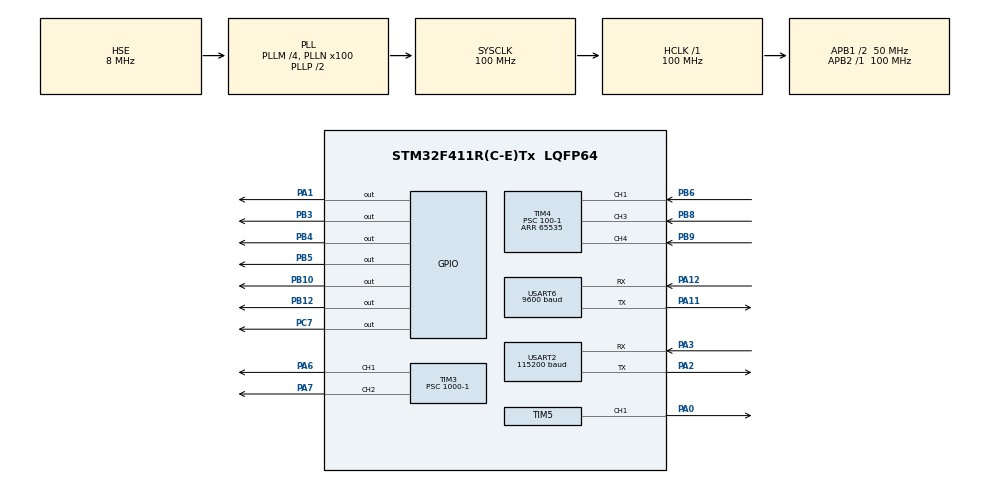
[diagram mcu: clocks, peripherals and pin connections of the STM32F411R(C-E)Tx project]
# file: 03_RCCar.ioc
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Dma.Request0=USART6_RX
Dma.USART6_RX.0.Direction=DMA_PERIPH_TO_MEMORY
Dma.USART6_RX.0.FIFOMode=DMA_FIFOMODE_DISABLE
Dma.USART6_RX.0.Instance=DMA2_Stream1
Dma.USART6_RX.0.MemDataAlignment=DMA_MDATAALIGN_BYTE
Dma.USART6_RX.0.MemInc=DMA_MINC_ENABLE
Dma.USART6_RX.0.Mode=DMA_NORMAL
Dma.USART6_RX.0.PeriphDataAlignment=DMA_PDATAALIGN_BYTE
Dma.USART6_RX.0.PeriphInc=DMA_PINC_DISABLE
Dma.USART6_RX.0.Priority=DMA_PRIORITY_LOW
FREERTOS.Tasks01=defaultTask,24,128,StartDefaultTask,Default,NULL,Dynamic,NULL,NULL;UltrasonicTask,24,128,Ultrasonic,Default,NULL,Dynamic,NULL,NULL;AutoRunTask,24,128,AutoRun,Default,NULL,Dynamic,NULL,NULL;BuzzerTask,24,128,Buzzer,Default,NULL,Dynamic,NULL,NULL
FREERTOS.configUSE_NEWLIB_REENTRANT=1
Mcu.Family=STM32F4
Mcu.Name=STM32F411R(C-E)Tx
Mcu.Package=LQFP64
NVIC.DMA2_Stream1_IRQn=true\:5\:0\:false\:false\:true\:true\:false\:true\:true
NVIC.PriorityGroup=NVIC_PRIORITYGROUP_4
NVIC.TIM1_UP_TIM10_IRQn=true\:15\:0\:false\:false\:true\:false\:true\:true\:true
NVIC.TIM4_IRQn=true\:5\:0\:false\:false\:true\:true\:true\:true\:true
NVIC.TimeBase=TIM1_UP_TIM10_IRQn
NVIC.TimeBaseIP=TIM10
NVIC.USART2_IRQn=true\:5\:0\:false\:false\:true\:true\:true\:true\:true
NVIC.USART6_IRQn=true\:5\:0\:false\:false\:true\:true\:true\:true\:true
PA0-WKUP.Signal=S_TIM5_CH1
PA1.Signal=GPIO_Output
PA11.Mode=Asynchronous
PA11.Signal=USART6_TX
PA12.Mode=Asynchronous
PA12.Signal=USART6_RX
PA13.Mode=Serial_Wire
PA13.Signal=SYS_JTMS-SWDIO
PA14.Mode=Serial_Wire
PA14.Signal=SYS_JTCK-SWCLK
PA2.Mode=Asynchronous
PA2.Signal=USART2_TX
PA3.Mode=Asynchronous
PA3.Signal=USART2_RX
PA6.Signal=S_TIM3_CH1
PA7.Signal=S_TIM3_CH2
PB10.Signal=GPIO_Output
PB12.Signal=GPIO_Output
PB3.Signal=GPIO_Output
PB4.Signal=GPIO_Output
PB5.Signal=GPIO_Output
PB6.Signal=S_TIM4_CH1
PB8.Signal=S_TIM4_CH3
PB9.Signal=S_TIM4_CH4
PC7.Signal=GPIO_Output
PH0\ -\ OSC_IN.Mode=HSE-External-Oscillator
PH0\ -\ OSC_IN.Signal=RCC_OSC_IN
PH1\ -\ OSC_OUT.Mode=HSE-External-Oscillator
PH1\ -\ OSC_OUT.Signal=RCC_OSC_OUT
ProjectManager.HeapSize=0x200
ProjectManager.StackSize=0x400
ProjectManager.TargetToolchain=STM32CubeIDE
RCC.48MHZClocksFreq_Value=50000000
RCC.AHBFreq_Value=100000000
RCC.APB1CLKDivider=RCC_HCLK_DIV2
RCC.APB1Freq_Value=50000000
RCC.APB1TimFreq_Value=100000000
RCC.APB2Freq_Value=100000000
RCC.APB2TimFreq_Value=100000000
RCC.CortexFreq_Value=100000000
RCC.HCLKFreq_Value=100000000
RCC.HSE_VALUE=8000000
RCC.HSI_VALUE=16000000
RCC.LSE_VALUE=32768
RCC.PLLM=4
RCC.PLLN=100
RCC.PLLSourceVirtual=RCC_PLLSOURCE_HSE
RCC.RCC_RTC_Clock_Source=RCC_RTCCLKSOURCE_LSI
RCC.RCC_RTC_Clock_SourceVirtual=RCC_RTCCLKSOURCE_LSI
RCC.SYSCLKFreq_VALUE=100000000
RCC.SYSCLKSource=RCC_SYSCLKSOURCE_PLLCLK
RCC.VCOOutputFreq_Value=200000000
SH.S_TIM3_CH1.0=TIM3_CH1,PWM Generation1 CH1
SH.S_TIM3_CH2.0=TIM3_CH2,PWM Generation2 CH2
SH.S_TIM4_CH1.0=TIM4_CH1,Input_Capture1_from_TI1
SH.S_TIM4_CH3.0=TIM4_CH3,Input_Capture3_from_TI3
SH.S_TIM4_CH4.0=TIM4_CH4,Input_Capture4_from_TI4
SH.S_TIM5_CH1.0=TIM5_CH1,PWM Generation1 CH1
TIM3.Channel-PWM\ Generation1\ CH1=TIM_CHANNEL_1
TIM3.Channel-PWM\ Generation2\ CH2=TIM_CHANNEL_2
TIM3.Period=1000-1
TIM3.Prescaler=1000-1
TIM4.Channel-Input_Capture1_from_TI1=TIM_CHANNEL_1
TIM4.Channel-Input_Capture3_from_TI3=TIM_CHANNEL_3
TIM4.Channel-Input_Capture4_from_TI4=TIM_CHANNEL_4
TIM4.Period=65535
TIM4.Prescaler=100-1
TIM5.Channel-PWM\ Generation1\ CH1=TIM_CHANNEL_1
TIM5.Period=1000-1
TIM5.Prescaler=0
TIM5.Pulse-PWM\ Generation1\ CH1=500-1
USART2.BaudRate=115200
USART2.VirtualMode=VM_ASYNC
USART6.BaudRate=9600
USART6.VirtualMode=VM_ASYNC
VP_FREERTOS_VS_CMSIS_V2.Mode=CMSIS_V2
VP_SYS_VS_tim10.Mode=TIM10
VP_TIM3_VS_ClockSourceINT.Mode=Internal
VP_TIM4_VS_ClockSourceINT.Mode=Internal
VP_TIM5_VS_ClockSourceINT.Mode=Internal
board=custom

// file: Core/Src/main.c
/* USER CODE BEGIN Header */
/**
  ******************************************************************************
  * @file           : main.c
  * @brief          : Main program body
  ******************************************************************************
  * @attention
  *
  * Copyright (c) 2025 STMicroelectronics.
  * All rights reserved.
  *
  * This software is licensed under terms that can be found in the LICENSE file
  * in the root directory of this software component.
  * If no LICENSE file comes with this software, it is provided AS-IS.
  *
  ******************************************************************************
  */
/* USER CODE END Header */
#include "main.h"
#include "cmsis_os.h"
#include "dma.h"
#include "tim.h"
#include "usart.h"
#include "gpio.h"

/* USER CODE BEGIN Includes */
#include "hw.h"

/* USER CODE END Includes */

void SystemClock_Config(void);
void MX_FREERTOS_Init(void);

int main(void)
{

  /* MCU Configuration--------------------------------------------------------*/

  /* Reset of all peripherals, Initializes the Flash interface and the Systick. */
  HAL_Init();

  /* Configure the system clock */
  SystemClock_Config();

  /* Initialize all configured peripherals */
  MX_GPIO_Init();
  MX_DMA_Init();
  MX_USART2_UART_Init();
  MX_USART6_UART_Init();
  MX_TIM3_Init();
  MX_TIM4_Init();
  MX_TIM5_Init();
  /* USER CODE BEGIN 2 */
  hwInit();
  /* USER CODE END 2 */

  /* Init scheduler */
  osKernelInitialize();

  /* Call init function for freertos objects (in cmsis_os2.c) */
  MX_FREERTOS_Init();

  /* Start scheduler */
  osKernelStart();

  /* We should never get here as control is now taken by the scheduler */

  /* Infinite loop */
  while (1)
  {

  }
}

void SystemClock_Config(void)
{
  RCC_OscInitTypeDef RCC_OscInitStruct = {0};
  RCC_ClkInitTypeDef RCC_ClkInitStruct = {0};

  /** Configure the main internal regulator output voltage
  */
  __HAL_RCC_PWR_CLK_ENABLE();
  __HAL_PWR_VOLTAGESCALING_CONFIG(PWR_REGULATOR_VOLTAGE_SCALE1);

  /** Initializes the RCC Oscillators according to the specified parameters
  * in the RCC_OscInitTypeDef structure.
  */
  RCC_OscInitStruct.OscillatorType = RCC_OSCILLATORTYPE_HSE;
  RCC_OscInitStruct.HSEState = RCC_HSE_ON;
  RCC_OscInitStruct.PLL.PLLState = RCC_PLL_ON;
  RCC_OscInitStruct.PLL.PLLSource = RCC_PLLSOURCE_HSE;
  RCC_OscInitStruct.PLL.PLLM = 4;
  RCC_OscInitStruct.PLL.PLLN = 100;
  RCC_OscInitStruct.PLL.PLLP = RCC_PLLP_DIV2;
  RCC_OscInitStruct.PLL.PLLQ = 4;
  if (HAL_RCC_OscConfig(&RCC_OscInitStruct) != HAL_OK)
  {
    Error_Handler();
  }

  /** Initializes the CPU, AHB and APB buses clocks
  */
  RCC_ClkInitStruct.ClockType = RCC_CLOCKTYPE_HCLK|RCC_CLOCKTYPE_SYSCLK
                              |RCC_CLOCKTYPE_PCLK1|RCC_CLOCKTYPE_PCLK2;
  RCC_ClkInitStruct.SYSCLKSource = RCC_SYSCLKSOURCE_PLLCLK;
  RCC_ClkInitStruct.AHBCLKDivider = RCC_SYSCLK_DIV1;
  RCC_ClkInitStruct.APB1CLKDivider = RCC_HCLK_DIV2;
  RCC_ClkInitStruct.APB2CLKDivider = RCC_HCLK_DIV1;

  if (HAL_RCC_ClockConfig(&RCC_ClkInitStruct, FLASH_LATENCY_3) != HAL_OK)
  {
    Error_Handler();
  }
}

void HAL_TIM_PeriodElapsedCallback(TIM_HandleTypeDef *htim)
{
  if (htim->Instance == TIM10) {
    HAL_IncTick();
  }
}

void Error_Handler(void)
{
  __disable_irq();
  while (1)
  {
  }
}

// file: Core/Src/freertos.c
/* USER CODE BEGIN Header */
/**
  ******************************************************************************
  * File Name          : freertos.c
  * Description        : Code for freertos applications
  ******************************************************************************
  * @attention
  *
  * Copyright (c) 2025 STMicroelectronics.
  * All rights reserved.
  *
  * This software is licensed under terms that can be found in the LICENSE file
  * in the root directory of this software component.
  * If no LICENSE file comes with this software, it is provided AS-IS.
  *
  ******************************************************************************
  */
/* USER CODE END Header */

#include "FreeRTOS.h"
#include "task.h"
#include "main.h"
#include "cmsis_os.h"

/* USER CODE BEGIN Includes */
#include "hw.h"

/* USER CODE END Includes */

/* Definitions for defaultTask */
osThreadId_t defaultTaskHandle;
const osThreadAttr_t defaultTask_attributes = {
  .name = "defaultTask",
  .stack_size = 128 * 4,
  .priority = (osPriority_t) osPriorityNormal,
};
/* Definitions for UltrasonicTask */
osThreadId_t UltrasonicTaskHandle;
const osThreadAttr_t UltrasonicTask_attributes = {
  .name = "UltrasonicTask",
  .stack_size = 128 * 4,
  .priority = (osPriority_t) osPriorityNormal,
};
/* Definitions for AutoRunTask */
osThreadId_t AutoRunTaskHandle;
const osThreadAttr_t AutoRunTask_attributes = {
  .name = "AutoRunTask",
  .stack_size = 128 * 4,
  .priority = (osPriority_t) osPriorityNormal,
};
/* Definitions for BuzzerTask */
osThreadId_t BuzzerTaskHandle;
const osThreadAttr_t BuzzerTask_attributes = {
  .name = "BuzzerTask",
  .stack_size = 128 * 4,
  .priority = (osPriority_t) osPriorityNormal,
};

void StartDefaultTask(void *argument);
void Ultrasonic(void *argument);
void AutoRun(void *argument);
void Buzzer(void *argument);

void MX_FREERTOS_Init(void); /* (MISRA C 2004 rule 8.1) */

void MX_FREERTOS_Init(void) {

  /* Create the thread(s) */
  /* creation of defaultTask */
  defaultTaskHandle = osThreadNew(StartDefaultTask, NULL, &defaultTask_attributes);

  /* creation of UltrasonicTask */
  UltrasonicTaskHandle = osThreadNew(Ultrasonic, NULL, &UltrasonicTask_attributes);

  /* creation of AutoRunTask */
  AutoRunTaskHandle = osThreadNew(AutoRun, NULL, &AutoRunTask_attributes);

  /* creation of BuzzerTask */
  BuzzerTaskHandle = osThreadNew(Buzzer, NULL, &BuzzerTask_attributes);

}

void StartDefaultTask(void *argument)
{
  for(;;)
  {
    osDelay(1);
  }
}

void Ultrasonic(void *argument)
{
  /* USER CODE BEGIN Ultrasonic */
  osDelay(100);
  /* Infinite loop */
  for(;;)
  {
	Ultrasonic_Process();
    osDelay(1);
  }
  /* USER CODE END Ultrasonic */
}

void AutoRun(void *argument)
{
  /* USER CODE BEGIN AutoRun */
  /* Infinite loop */
  for(;;)
  {
	AutoRun_Process();
    osDelay(1);
  }
  /* USER CODE END AutoRun */
}

void Buzzer(void *argument)
{
  /* USER CODE BEGIN Buzzer */
  /* Infinite loop */
  for(;;)
  {
	Buzzer_Process();
    osDelay(1);
  }
  /* USER CODE END Buzzer */
}
